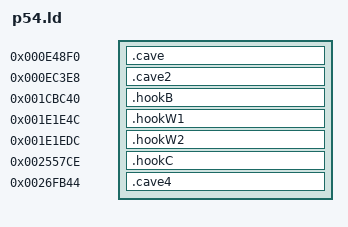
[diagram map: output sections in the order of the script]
SECTIONS {
  .cave 0xe48f0 : { *(.cave) }
  .cave2 0xec3e8 : { *(.cave2) }
  .hookB 0x1cbc40 : { *(.hookB) }
  .hookW1 0x1e1e4c : { *(.hookW1) }
  .hookW2 0x1e1edc : { *(.hookW2) }
  .hookC 0x2557ce : { *(.hookC) }
  .cave4 0x26fb44 : { *(.cave4) }
}
COTD = 0x3db03a; STRCPY = 0x3a2178; W52 = 0x1cbc53; W48 = 0x1cbc49;
ENT = 0xf6995; GETDOOR = 0x1b49f9; FAIL = 0x255773; RESUME = 0x2557d5;
WK1 = 0x1e1e5f; WN1 = 0x1e1e55; WK2 = 0x1e1eef; WN2 = 0x1e1ee5;
